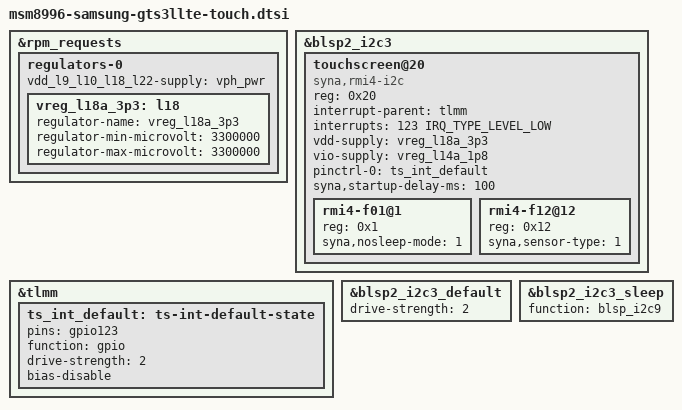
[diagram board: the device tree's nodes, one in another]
// SPDX-License-Identifier: BSD-3-Clause
/* Synaptics S5807 (RMI4) touchscreen. */

#include <dt-bindings/interrupt-controller/irq.h>

/* Test: Synaptics S5807 (RMI4) touchscreen on BLSP2 I2C3, on top of the display test. */

&rpm_requests {
	regulators-0 {
		/* touch controller analog supply (downstream tsp_avdd) */
		vreg_l18a_3p3: l18 {
			regulator-name = "vreg_l18a_3p3";
			regulator-min-microvolt = <3300000>;
			regulator-max-microvolt = <3300000>;
		};
	};
};

&blsp2_i2c3 {
	status = "okay";

	touchscreen@20 {
		compatible = "syna,rmi4-i2c";
		reg = <0x20>;
		#address-cells = <1>;
		#size-cells = <0>;

		interrupt-parent = <&tlmm>;
		interrupts = <123 IRQ_TYPE_LEVEL_LOW>;

		vdd-supply = <&vreg_l18a_3p3>;
		vio-supply = <&vreg_l14a_1p8>;

		pinctrl-names = "default";
		pinctrl-0 = <&ts_int_default>;

		syna,startup-delay-ms = <100>;

		rmi4-f01@1 {
			reg = <0x1>;
			syna,nosleep-mode = <1>;
		};

		rmi4-f12@12 {
			reg = <0x12>;
			syna,sensor-type = <1>;
		};
	};
};

&tlmm {
	/* downstream tsp_int_active: gpio123 */
	ts_int_default: ts-int-default-state {
		pins = "gpio123";
		function = "gpio";
		drive-strength = <2>;
		bias-disable;
	};
};

/* Stock touch I2C explicitly disables DMA. Avoid depending on the unrelated
 * BLSP2 DMA probe during this test.
 */
&blsp2_i2c3 {
	/delete-property/ dmas;
	/delete-property/ dma-names;
};

&blsp2_i2c3_default {
	drive-strength = <2>;
};

&blsp2_i2c3_sleep {
	function = "blsp_i2c9";
};

&rpm_requests {
	regulators-0 {
		vdd_l9_l10_l18_l22-supply = <&vph_pwr>;
	};
};
